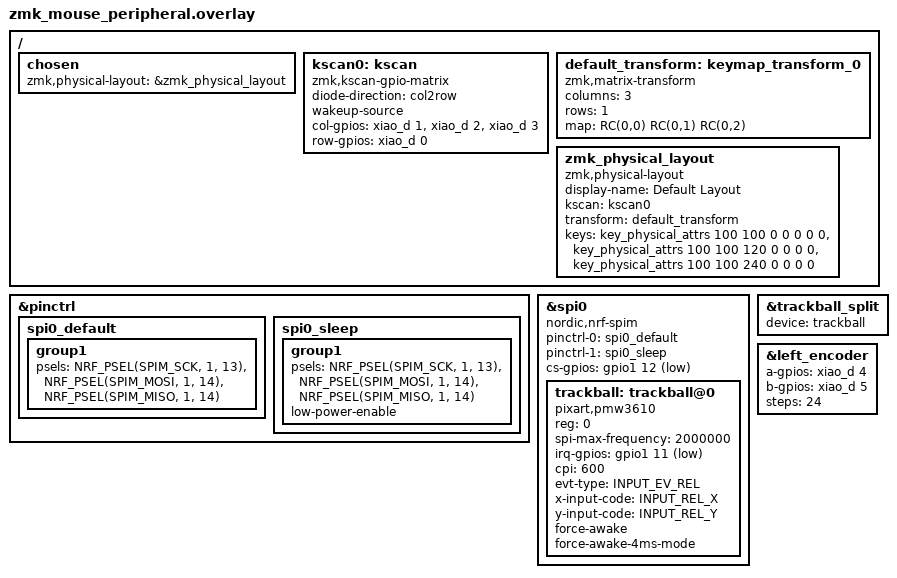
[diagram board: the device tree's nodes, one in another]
#include <dt-bindings/zmk/matrix_transform.h>
#include <physical_layouts.dtsi>
#include <zephyr/dt-bindings/input/input-event-codes.h>
#include <input/processors.dtsi>
#include <behaviors/input_gestures_accel.dtsi>
#include "zmk_mouse.dtsi"

#define ZMK_POINTING_DEFAULT_SCRL_VAL 100

/ {
    chosen {
        zmk,physical-layout = &zmk_physical_layout;
    };
    
    kscan0: kscan {
        compatible = "zmk,kscan-gpio-matrix";
        diode-direction = "col2row";
        wakeup-source;

        col-gpios
            = <&xiao_d  1 GPIO_ACTIVE_HIGH>
            , <&xiao_d  2 GPIO_ACTIVE_HIGH> 
            , <&xiao_d  3 GPIO_ACTIVE_HIGH> 
            ;
        row-gpios
            = <&xiao_d 0 (GPIO_ACTIVE_HIGH | GPIO_PULL_DOWN)> 
            ;
    };

    default_transform: keymap_transform_0 {
        compatible = "zmk,matrix-transform";
        columns = <3>;
        rows = <1>;               
        map = <
            RC(0,0) RC(0,1) RC(0,2)
        >;
    };

    zmk_physical_layout: zmk_physical_layout {
        compatible = "zmk,physical-layout";
        display-name = "Default Layout";
        kscan = <&kscan0>;
        transform = <&default_transform>;

        keys  //                 w   h    x    y     rot    rx    ry
        = <&key_physical_attrs 100 100    0    0       0     0     0>
        , <&key_physical_attrs 100 100  120    0       0     0     0>
        , <&key_physical_attrs 100 100  240    0       0     0     0>
        ;
    };
};

&pinctrl {
    spi0_default: spi0_default {
        group1 {
            psels = <NRF_PSEL(SPIM_SCK, 1, 13)>,
                <NRF_PSEL(SPIM_MOSI, 1, 14)>,
                <NRF_PSEL(SPIM_MISO, 1, 14)>;
        };
    };

    spi0_sleep: spi0_sleep {
        group1 {
            psels = <NRF_PSEL(SPIM_SCK, 1, 13)>,
                <NRF_PSEL(SPIM_MOSI, 1, 14)>,
                <NRF_PSEL(SPIM_MISO, 1, 14)>;
            low-power-enable;
        };
    };
};

&spi0 {
    status = "okay";
    compatible = "nordic,nrf-spim";
    pinctrl-0 = <&spi0_default>;
    pinctrl-1 = <&spi0_sleep>;
    pinctrl-names = "default", "sleep";
    cs-gpios = <&gpio1 12 GPIO_ACTIVE_LOW>;


    trackball: trackball@0 {
        status = "okay";
        compatible = "pixart,pmw3610";
        reg = <0>;
        spi-max-frequency = <2000000>;
        irq-gpios = <&gpio1 11 (GPIO_ACTIVE_LOW | GPIO_PULL_UP)>;
        cpi = <600>;
        // swap-xy; /* optional */
        // invert-x; /* optional */
        // invert-y; /* optional */
        evt-type = <INPUT_EV_REL>;
        x-input-code = <INPUT_REL_X>;
        y-input-code = <INPUT_REL_Y>;

        force-awake;
        /* keep the sensor awake while ZMK activity state is ACTIVE,
           fallback to normal downshift mode after ZMK goes into IDLE / SLEEP mode.
           thus, the sensor would be a `wakeup-source` */

        force-awake-4ms-mode;
        /* while force-awake is acitvated, enable this mode to force sampling per 
           4ms, where the default sampling rate is 8ms. */
        /* NOTE: apply this mode if you need 250Hz with direct USB connection. */
    };
};

&trackball_split {
    device = <&trackball>;
};

&left_encoder {
    a-gpios = <&xiao_d 4 (GPIO_ACTIVE_HIGH | GPIO_PULL_UP)>;
    b-gpios = <&xiao_d 5 (GPIO_ACTIVE_HIGH | GPIO_PULL_UP)>;
    steps = <24>;
    status = "okay";
};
